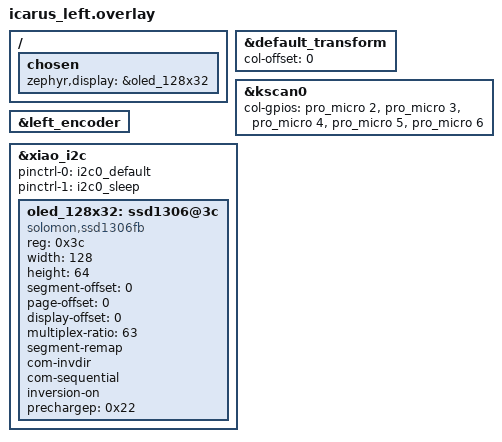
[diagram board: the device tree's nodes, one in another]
#include "icarus.dtsi"

&default_transform {
    col-offset = <0>;
};

&kscan0 {
    status = "okay";
    col-gpios
        = <&pro_micro 2 GPIO_ACTIVE_HIGH>
        , <&pro_micro 3 GPIO_ACTIVE_HIGH>
        , <&pro_micro 4 GPIO_ACTIVE_HIGH>
        , <&pro_micro 5 GPIO_ACTIVE_HIGH>
        , <&pro_micro 6 GPIO_ACTIVE_HIGH>
        ;
};

&left_encoder {
    status = "okay";
};

&xiao_i2c {
    //compatible = "nordic,nrf-twim"; // I2C controller instead of generic
    status = "okay";
    pinctrl-0 = <&i2c0_default>;
    pinctrl-1 = <&i2c0_sleep>;
    pinctrl-names = "default", "sleep";
    //clock-frequency = <I2C_BITRATE_STANDARD>;

    /* Nodes using the bus go here */
    oled_128x32: ssd1306@3c {
        compatible = "solomon,ssd1306fb";
        reg = <0x3c>;
        width = <128>;
        height = <64>;
        segment-offset = <0>;
        page-offset = <0>;
        display-offset = <0>;
        multiplex-ratio = <63>;
        segment-remap;
        com-invdir;
        com-sequential;
        inversion-on;
        prechargep = <0x22>;
    };

};

/ {
    chosen {
        zephyr,display = &oled_128x32;
    };
};
